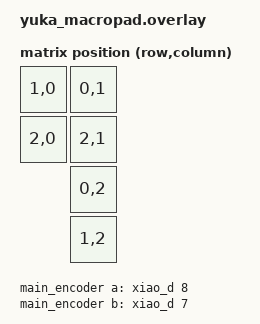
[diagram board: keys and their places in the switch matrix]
// This file was generated from a template. Edit it to match your keyboard.
// See https://zmk.dev/docs/development/hardware-integration/new-shield for more
// instructions.

#include <dt-bindings/zmk/matrix_transform.h>

#include "yuka_macropad-layouts.dtsi"

/ {
    chosen {
//        zmk,default-output = &bt;
        zephyr,settings-partition = &storage_partition;
        zmk,physical-layout = &default_layout;
        zmk,battery = &non_lipo_battery;
        zmk,sensors = &sensors;
        zmk,kscan = &kscan;
    };

    vbatt: vbatt {
          status = "disabled";
//        compatible = "zmk,battery-voltage-divider";
//        compatible = "zmk,non-lipo-battery";
//        io-channels = <&adc 0>;
//        power-gpios; // unset
//        power-gpios = <&xiao_d 0 GPIO_ACTIVE_HIGH>;
//        output-ohms = <470000>;
//        full-ohms = <(1000000 + 470000)>;
        // For Ni-Mh 1U
//        mv-to-pct-thresholds = <1100 1150 1200 1220 1240 1260 1280 1300 1320 1350 1400>;
    };

    non_lipo_battery: non_lipo_battery {
        compatible = "zmk,non-lipo-battery";
        io-channels = <&adc 0>;
//        power-gpios = <&gpio0 1 GPIO_ACTIVE_HIGH>;  // Replace with your GPIO
    };

    kscan: kscan {
        compatible = "zmk,kscan-gpio-charlieplex";
        gpios
        = <&xiao_d 2 (GPIO_ACTIVE_HIGH)>
        , <&xiao_d 3 (GPIO_ACTIVE_HIGH)>
        , <&xiao_d 4 (GPIO_ACTIVE_HIGH)>
        ;
        wakeup-source;
        interrupt-gpios = <&xiao_d 1 (GPIO_ACTIVE_HIGH | GPIO_PULL_DOWN)>;
    };

    main_encoder: encoder {
        compatible = "alps,ec11";
        a-gpios = <&xiao_d 8 (GPIO_ACTIVE_HIGH | GPIO_PULL_UP)>; // A相: D8
        b-gpios = <&xiao_d 7 (GPIO_ACTIVE_HIGH | GPIO_PULL_UP)>; // B相: D7
        steps = <24>;
        status = "okay"; // のサンプルから status を有効化
    };

    sensors: sensors {
        compatible = "zmk,keymap-sensors";
        sensors = <&main_encoder>;
        triggers-per-rotation = <24>;
    };

//    kscan: kscan {
//        // If the hardware does not use a switch matrix, change this to the
//        // appropriate driver and update the properties below to match.
//        // See https://zmk.dev/docs/config/kscan for supported key scan drivers.
//        compatible = "zmk,kscan-gpio-matrix";
//        // Set this to "col2row" or "row2col" to match the hardware. If using
//        // "row2col", change the col-gpios to (GPIO_ACTIVE_HIGH | GPIO_PULL_DOWN)
//        // and the row-gpios to GPIO_ACTIVE_HIGH.
//        diode-direction = "col2row";
//        wakeup-source;
//
//        // Replace these comments with the GPIO pins in the matrix.
//        // See https://zmk.dev/docs/development/hardware-integration/new-shield#shield-overlays
//        col-gpios
//            = <&xiao_d 0 GPIO_ACTIVE_HIGH>
//            , <&xiao_d 0 GPIO_ACTIVE_HIGH>
//            ;
//
//        row-gpios
//            = <&xiao_d 0 (GPIO_ACTIVE_HIGH | GPIO_PULL_DOWN)>
//            , <&xiao_d 0 (GPIO_ACTIVE_HIGH | GPIO_PULL_DOWN)>
//            ;
//    };

    default_transform: default_transform {
        // See https://zmk.dev/docs/development/hardware-integration/new-shield#matrix-transform
        // for how to configure this
        compatible = "zmk,matrix-transform";
        columns = <3>;
        rows = <3>;
        map = <
            RC(1, 0)    RC(0, 1)    // 1段目: SW1 (左) , SW3 (右)
            RC(2, 0)    RC(2, 1)    // 2段目: SW2 (左) , SW4 (右)
                        RC(0, 2)    // 3段目: (なし)   , SW5 (右)
                        RC(1, 2)    // 4段目: (なし)   , SW6 (右)
        >;
    };
};

&adc {
    status = "okay";
};
